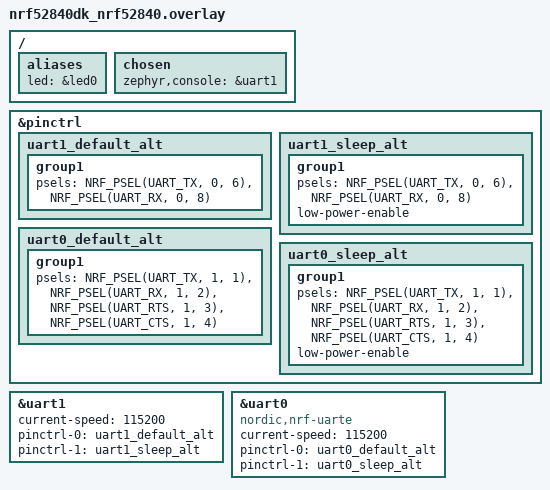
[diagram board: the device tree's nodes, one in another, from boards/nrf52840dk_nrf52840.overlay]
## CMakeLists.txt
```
#
# Copyright (c) 2025 Nordic Semiconductor ASA
#
# SPDX-License-Identifier: LicenseRef-Nordic-5-Clause
#

cmake_minimum_required(VERSION 3.20.0)

find_package(Zephyr REQUIRED HINTS $ENV{ZEPHYR_BASE})

project(uarte_suspend)

target_sources(app PRIVATE src/main.c)
```

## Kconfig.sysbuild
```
#
# Copyright (c) 2025 Nordic Semiconductor ASA
#
# SPDX-License-Identifier: LicenseRef-Nordic-5-Clause
#

config REMOTE_BOARD
	string
	default "$(BOARD)/nrf54h20/cpurad" if SOC_NRF54H20_CPUAPP

source "share/sysbuild/Kconfig"
```

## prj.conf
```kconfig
CONFIG_SERIAL=y
CONFIG_MAIN_STACK_SIZE=2048
CONFIG_UART_ASYNC_API=y

CONFIG_PM=y
CONFIG_PM_DEVICE=y
CONFIG_PM_DEVICE_RUNTIME=y
CONFIG_POWEROFF=y

CONFIG_BOOT_BANNER=n
CONFIG_NCS_BOOT_BANNER=n
CONFIG_ASSERT=y

# Enable for debugging purposes only
CONFIG_PRINTK=n
CONFIG_LOG=n
CONFIG_CONSOLE=n
CONFIG_UART_CONSOLE=n
```

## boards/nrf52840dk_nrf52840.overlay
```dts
/*
 * Copyright (c) 2025 Nordic Semiconductor ASA
 *
 * SPDX-License-Identifier: LicenseRef-Nordic-5-Clause
 */

/ {
	aliases {
		led = &led0;
		/delete-property/ led1;
	};
};

/delete-node/ &led1;

&pinctrl {
	uart1_default_alt: uart1_default_alt {
		group1 {
			psels = <NRF_PSEL(UART_TX, 0, 6)>,
				<NRF_PSEL(UART_RX, 0, 8)>;
		};
	};

	uart1_sleep_alt: uart1_sleep_alt {
		group1 {
			psels = <NRF_PSEL(UART_TX, 0, 6)>,
				<NRF_PSEL(UART_RX, 0, 8)>;
			low-power-enable;
		};
	};

	uart0_default_alt: uart0_default_alt {
		group1 {
			psels = <NRF_PSEL(UART_TX, 1, 1)>,
				<NRF_PSEL(UART_RX, 1, 2)>,
				<NRF_PSEL(UART_RTS, 1, 3)>,
				<NRF_PSEL(UART_CTS, 1, 4)>;
		};
	};

	uart0_sleep_alt: uart0_sleep_alt {
		group1 {
			psels = <NRF_PSEL(UART_TX, 1, 1)>,
				<NRF_PSEL(UART_RX, 1, 2)>,
				<NRF_PSEL(UART_RTS, 1, 3)>,
				<NRF_PSEL(UART_CTS, 1, 4)>;
			low-power-enable;
		};
	};
};

/ {
	chosen {
		zephyr,console = &uart1;
	};
};

&uart1 {
	current-speed = <115200>;
	status = "okay";
	pinctrl-0 = <&uart1_default_alt>;
	pinctrl-1 = <&uart1_sleep_alt>;
	pinctrl-names = "default", "sleep";
};

dut: &uart0 {
	compatible = "nordic,nrf-uarte";
	current-speed = <115200>;
	status = "okay";
	pinctrl-0 = <&uart0_default_alt>;
	pinctrl-1 = <&uart0_sleep_alt>;
	pinctrl-names = "default", "sleep";
};
```

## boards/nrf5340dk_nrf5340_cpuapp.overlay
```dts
/*
 * Copyright (c) 2025 Nordic Semiconductor ASA
 *
 * SPDX-License-Identifier: LicenseRef-Nordic-5-Clause
 */

/ {
	aliases {
		led = &led0;
		/delete-property/ led1;
	};
};

/delete-node/ &led1;

&pinctrl {
	uart1_default_alt: uart1_default_alt {
		group1 {
			psels = <NRF_PSEL(UART_TX, 0, 4)>,
				<NRF_PSEL(UART_RX, 0, 5)>,
				<NRF_PSEL(UART_RTS, 0, 6)>,
				<NRF_PSEL(UART_CTS, 0, 7)>;
		};
	};

	uart1_sleep_alt: uart1_sleep_alt {
		group1 {
			psels = <NRF_PSEL(UART_TX, 0, 4)>,
				<NRF_PSEL(UART_RX, 0, 5)>,
				<NRF_PSEL(UART_RTS, 0, 6)>,
				<NRF_PSEL(UART_CTS, 0, 7)>;
			low-power-enable;
		};
	};
};

dut: &uart1 {
	current-speed = <115200>;
	compatible = "nordic,nrf-uarte";
	status = "okay";
	pinctrl-0 = <&uart1_default_alt>;
	pinctrl-1 = <&uart1_sleep_alt>;
	pinctrl-names = "default", "sleep";
	hw-flow-control;
};

&vregmain {
	regulator-initial-mode = <NRF5X_REG_MODE_LDO>;
};
```

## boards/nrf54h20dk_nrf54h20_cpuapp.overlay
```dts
/*
 * Copyright (c) 2025 Nordic Semiconductor ASA
 *
 * SPDX-License-Identifier: LicenseRef-Nordic-5-Clause
 */

/ {
	aliases {
		led = &led0;
		/delete-property/ led1;
	};
};

/delete-node/ &led1;

&cpuapp_dma_region {
	status = "okay";
};

/* UART device used for test
 * not the default UART assignment for the LD
 */
&pinctrl {
	uart135_default_alt: uart135_default_alt {
		group1 {
			psels = <NRF_PSEL(UART_TX, 0, 6)>,
				<NRF_PSEL(UART_RX, 0, 7)>,
				<NRF_PSEL(UART_RTS, 0, 8)>,
				<NRF_PSEL(UART_CTS, 0, 9)>;
		};
	};

	uart135_sleep_alt: uart135_sleep_alt {
		group1 {
			psels = <NRF_PSEL(UART_TX, 0, 6)>,
				<NRF_PSEL(UART_RX, 0, 7)>,
				<NRF_PSEL(UART_RTS, 0, 8)>,
				<NRF_PSEL(UART_CTS, 0, 9)>;
			low-power-enable;
		};
	};
};

dut: &uart135 {
	status = "okay";
	memory-regions = <&cpuapp_dma_region>;
	pinctrl-0 = <&uart135_default_alt>;
	pinctrl-1 = <&uart135_sleep_alt>;
	pinctrl-names = "default", "sleep";
	current-speed = <115200>;
	hw-flow-control;
};
```

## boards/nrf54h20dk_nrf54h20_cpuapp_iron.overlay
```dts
/*
 * Copyright (c) 2025 Nordic Semiconductor ASA
 *
 * SPDX-License-Identifier: LicenseRef-Nordic-5-Clause
 */

/ {
	aliases {
		led = &led0;
		/delete-property/ led1;
	};
};

/delete-node/ &led1;

&cpuapp_dma_region {
	status="okay";
};

/* UART device used for test
 * not the default UART assignment for the LD
 */
&pinctrl {
	uart135_default_alt: uart135_default_alt {
		group1 {
			psels = <NRF_PSEL(UART_TX, 0, 6)>,
				<NRF_PSEL(UART_RX, 0, 7)>,
				<NRF_PSEL(UART_RTS, 0, 8)>,
				<NRF_PSEL(UART_CTS, 0, 9)>;
		};
	};

	uart135_sleep_alt: uart135_sleep_alt {
		group1 {
			psels = <NRF_PSEL(UART_TX, 0, 6)>,
				<NRF_PSEL(UART_RX, 0, 7)>,
				<NRF_PSEL(UART_RTS, 0, 8)>,
				<NRF_PSEL(UART_CTS, 0, 9)>;
			low-power-enable;
		};
	};
};

dut: &uart135 {
	status = "okay";
	memory-regions = <&cpuapp_dma_region>;
	pinctrl-0 = <&uart135_default_alt>;
	pinctrl-1 = <&uart135_sleep_alt>;
	pinctrl-names = "default", "sleep";
	current-speed = <115200>;
	hw-flow-control;
};
```

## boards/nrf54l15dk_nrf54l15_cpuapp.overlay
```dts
/*
 * Copyright (c) 2025 Nordic Semiconductor ASA
 *
 * SPDX-License-Identifier: LicenseRef-Nordic-5-Clause
 */

/ {
	aliases {
		led = &led0;
		/delete-property/ led1;
	};
};

/delete-node/ &led1;

&pinctrl {
	uart21_default: uart21_default {
		group1 {
			psels = <NRF_PSEL(UART_TX, 1, 10)>,
				<NRF_PSEL(UART_RX, 1, 11)>,
				<NRF_PSEL(UART_RTS, 1, 8)>,
				<NRF_PSEL(UART_CTS, 1, 9)>;
		};
	};

	uart21_sleep: uart21_sleep {
		group1 {
			psels = <NRF_PSEL(UART_TX, 1, 10)>,
				<NRF_PSEL(UART_RX, 1, 11)>,
				<NRF_PSEL(UART_RTS, 1, 8)>,
				<NRF_PSEL(UART_CTS, 1, 9)>;
			low-power-enable;
		};
	};
};

dut: &uart21 {
	status = "okay";
	current-speed = <115200>;
	pinctrl-0 = <&uart21_default>;
	pinctrl-1 = <&uart21_sleep>;
	pinctrl-names = "default", "sleep";
	hw-flow-control;
};
```

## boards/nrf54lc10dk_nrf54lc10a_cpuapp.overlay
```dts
/*
 * Copyright (c) 2026 Nordic Semiconductor ASA
 *
 * SPDX-License-Identifier: LicenseRef-Nordic-5-Clause
 */

/ {
	aliases {
		led = &led0;
		/delete-property/ led1;
	};
};

/delete-node/ &led1;

/* Test requires following loopback:
 * P1.10 - P1.11
 */

&pinctrl {
	uart21_default_alt: uart21_default_alt {
		group1 {
			psels = <NRF_PSEL(UART_TX, 1, 10)>,
				<NRF_PSEL(UART_RX, 1, 11)>;
		};
	};

	uart21_sleep_alt: uart21_sleep_alt {
		group1 {
			psels = <NRF_PSEL(UART_TX, 1, 10)>,
				<NRF_PSEL(UART_RX, 1, 11)>;
			low-power-enable;
		};
	};
};

dut: &uart21 {
	status = "okay";
	pinctrl-0 = <&uart21_default_alt>;
	pinctrl-1 = <&uart21_sleep_alt>;
	pinctrl-names = "default", "sleep";
	current-speed = <115200>;
};
```

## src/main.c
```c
/*
 * Copyright (c) 2025 Nordic Semiconductor ASA
 *
 * SPDX-License-Identifier: LicenseRef-Nordic-5-Clause
 */

#include <zephyr/drivers/uart.h>
#include <zephyr/pm/device_runtime.h>
#include <zephyr/pm/device.h>
#include <zephyr/kernel.h>
#include <zephyr/logging/log.h>
#include <zephyr/drivers/gpio.h>

/* Note: logging is normally disabled for this test
 * Enable only for debugging purposes
 */
LOG_MODULE_REGISTER(uarte_suspend);

static const struct gpio_dt_spec led = GPIO_DT_SPEC_GET(DT_ALIAS(led), gpios);

#if DT_NODE_EXISTS(DT_NODELABEL(dut))
#define UART_NODE DT_NODELABEL(dut)
#else
#error Improper device tree configuration, UARTE test node not available
#endif

#define UART_ACTION_BASE_TIMEOUT_US 1000
#define TEST_BUFFER_LEN		    10

static const struct device *const uart_dev = DEVICE_DT_GET(UART_NODE);

const uint8_t test_pattern[TEST_BUFFER_LEN] = {0x11, 0x12, 0x13, 0x14, 0x15,
					       0x16, 0x17, 0x18, 0x19, 0x20};
static uint8_t test_buffer[TEST_BUFFER_LEN];
static volatile uint8_t uart_error_counter;

/*
 * Callback function for UART async transmission
 */
static void async_uart_callback(const struct device *dev, struct uart_event *evt, void *user_data)
{
	printk("Callback !\n");
	switch (evt->type) {
	case UART_TX_DONE:
		printk("UART_TX_DONE\n");
		break;
	case UART_TX_ABORTED:
		printk("UART_TX_ABORTED\n");
		printk("Callback should not enter here\n");
		__ASSERT_NO_MSG(1 == 0);
		break;
	case UART_RX_RDY:
		printk("UART_RX_RDY\n");
		for (int index = 0; index < TEST_BUFFER_LEN; index++) {
			printk("test_pattern[%d]=%d\n", index, test_pattern[index]);
			printk("test_buffer[%d]=%d\n", index, test_buffer[index]);
			if (test_buffer[index] != test_pattern[index]) {
				printk("Recieived data byte %d does not match pattern 0x%x != "
				       "0x%x\n",
				       index, test_buffer[index], test_pattern[index]);
				__ASSERT_NO_MSG(test_buffer[index] == test_pattern[index]);
			}
		}
		break;
	case UART_RX_BUF_RELEASED:
		printk("UART_RX_BUF_RELEASED\n");
		break;
	case UART_RX_BUF_REQUEST:
		printk("UART_RX_BUF_REQUEST\n");
		break;
	case UART_RX_DISABLED:
		printk("UART_RX_DISABLED\n");
		break;
	default:
		break;
	}
}

/* Helper function for enabling UART RX */
void enable_uart_rx(void)
{
	int err;

	printk("Enable UART RX\n");
	err = uart_rx_enable(uart_dev, test_buffer, TEST_BUFFER_LEN,
			     5 * UART_ACTION_BASE_TIMEOUT_US);
	if (err != 0) {
		printk("Unexpected error when enabling UART RX: %d\n", err);
	}
}

/* Helper function for disabling UART RX */
void disable_uart_rx(void)
{
	int err;

	k_busy_wait(250000);
	printk("Disable UART RX\n");
	err = uart_rx_disable(uart_dev);
	if (err != 0) {
		printk("Unexpected error when disabling RX: %d\n", err);
	}
	k_busy_wait(250000);
}

int main(void)
{
	int err;

	err = gpio_is_ready_dt(&led);
	__ASSERT(err, "Error: GPIO Device not ready");

	err = gpio_pin_configure_dt(&led, GPIO_OUTPUT_ACTIVE);
	__ASSERT(err == 0, "Could not configure led GPIO");

	printk("Hello World! %s\n", CONFIG_BOARD_TARGET);
	printk("UART instance: %s\n", uart_dev->name);
	k_msleep(250);

	err = uart_callback_set(uart_dev, async_uart_callback, NULL);
	if (err != 0) {
		printk("Unexpected error when setting callback %d\n", err);
		__ASSERT_NO_MSG(err == 0);
	}

	while (1) {
		printk("Hello\n");
		enable_uart_rx();

		printk("UART test transmission\n");
		err = uart_tx(uart_dev, test_pattern, TEST_BUFFER_LEN, UART_ACTION_BASE_TIMEOUT_US);
		if (err != 0) {
			printk("Unexpected error when sending UART TX data: %d\n", err);
			__ASSERT_NO_MSG(err == 0);
		}
		disable_uart_rx();
		err = pm_device_action_run(uart_dev, PM_DEVICE_ACTION_SUSPEND);
		printk("Good night\n");
		gpio_pin_set_dt(&led, 0);
		k_msleep(1000);
		gpio_pin_set_dt(&led, 1);
		err = pm_device_action_run(uart_dev, PM_DEVICE_ACTION_RESUME);
	}

	return 0;
}
```
